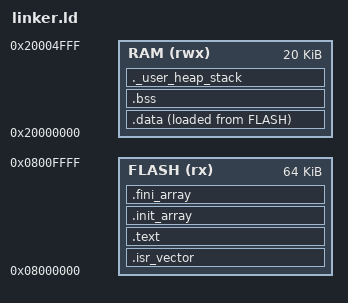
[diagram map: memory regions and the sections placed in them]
/* linker.ld
 * Default: STM32F103C8T6 at 0x08000000 (bare-metal, ST-Link). The "8" means 64K
 * of flash per the datasheet. Many of these chips have 128K fitted, but only 64K
 * is guaranteed, so this is what the link checks. Use 128K on a CB part, or on a
 * chip you have tested yourself.
 * If you flash via a bootloader, offset ORIGIN accordingly. */

MEMORY
{
  FLASH (rx)  : ORIGIN = 0x08000000, LENGTH = 64K
  RAM   (rwx) : ORIGIN = 0x20000000, LENGTH = 20K
}

_Min_Heap_Size  = 0x200;
_Min_Stack_Size = 0x400;

ENTRY(Reset_Handler)

SECTIONS
{
  .isr_vector :
  {
    . = ALIGN(4);
    KEEP(*(.isr_vector))
    . = ALIGN(4);
  } > FLASH

  .text :
  {
    . = ALIGN(4);
    *(.text)
    *(.text*)
    *(.rodata)
    *(.rodata*)
    . = ALIGN(4);
    _etext = .;
  } > FLASH

  .init_array :
  {
    . = ALIGN(4);
    __init_array_start = .;
    KEEP(*(SORT(.init_array.*)))
    KEEP(*(.init_array))
    __init_array_end = .;
  } > FLASH

  .fini_array :
  {
    . = ALIGN(4);
    __fini_array_start = .;
    KEEP(*(SORT(.fini_array.*)))
    KEEP(*(.fini_array))
    __fini_array_end = .;
  } > FLASH

  _sidata = LOADADDR(.data);

  .data :
  {
    . = ALIGN(4);
    _sdata = .;
    *(.data)
    *(.data*)
    . = ALIGN(4);
    _edata = .;
  } > RAM AT> FLASH

  .bss :
  {
    . = ALIGN(4);
    _sbss = .;
    *(.bss)
    *(.bss*)
    *(COMMON)
    . = ALIGN(4);
    _ebss = .;
  } > RAM

  ._user_heap_stack :
  {
    . = ALIGN(8);
    PROVIDE(end = .);
    PROVIDE(_end = .);
    . = . + _Min_Heap_Size;
    . = . + _Min_Stack_Size;
    . = ALIGN(8);
  } > RAM
}

_estack = ORIGIN(RAM) + LENGTH(RAM);
